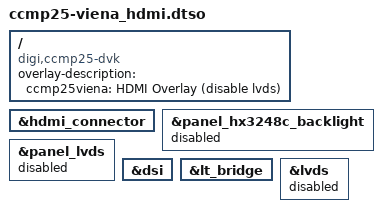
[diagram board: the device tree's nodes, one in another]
/dts-v1/;
/plugin/;

/ {
    compatible = "digi,ccmp25-dvk", "digi,ccmp25", "digi,ccmp2", "st,stm32mp255";

    fragment@0 {
        target-path = "/";
        __overlay__ {
            overlay-description = "ccmp25viena: HDMI Overlay (disable lvds)";
        };
    };
};

&hdmi_connector {
    status = "okay";
};

&panel_hx3248c_backlight {
    status = "disabled";
};

&panel_lvds {
    status = "disabled";
};

&dsi {
    status = "okay";
};

&lt_bridge {
    status = "okay";
};

&lvds {
    status = "disabled";
};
